# iqn_ail register map
Vendor: Texas Instruments
Peripheral module from a debugger description file (folder Keystone2).
Registers are 32-bit, read-only, no defined reset value unless marked. A register's access mark holds for its fields unless they carry their own. Offsets are as the file gives them; lines under a group give offsets from that group; [hi:lo] are bit positions; {n}, {i} and the like mark numbered series; 'fields as' and 'values as' point back to an identical list; <NAME> marks a mode.

## IQN_AIL (part 1 of 5)
0x3023C AIL_PHY_TM_Status_Register — (1 of 1, stride 0)
  [8:5] frm_state — Indicates that status of the Frame Sync state machine
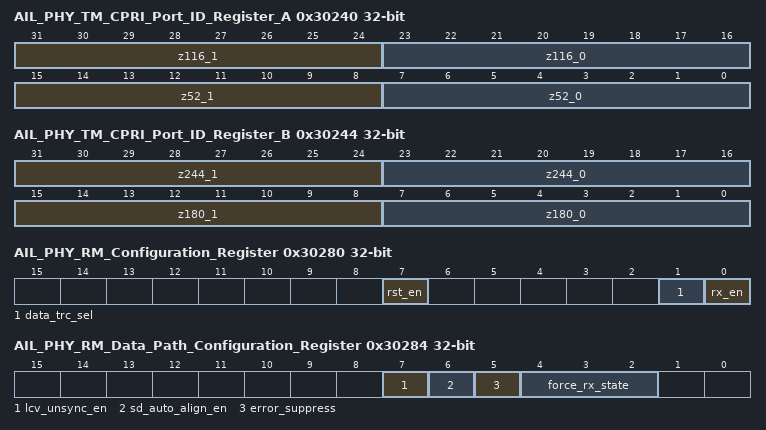
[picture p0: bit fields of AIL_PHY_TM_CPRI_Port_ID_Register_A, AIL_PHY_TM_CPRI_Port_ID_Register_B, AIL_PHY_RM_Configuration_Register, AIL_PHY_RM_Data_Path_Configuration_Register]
0x30240 AIL_PHY_TM_CPRI_Port_ID_Register_A rw — (1 of 1, stride 0)
  [31:24] z116_1 — Contains the Z.116.1 byte transmitted CPRI Port ID value
  [23:16] z116_0 — Contains the Z.116.0 byte transmitted CPRI Port ID value
  [15:8] z52_1 — Contains the Z.52.1 byte transmitted CPRI Port ID value
  [7:0] z52_0 — Contains the Z.52.0 byte transmitted CPRI Port ID value
0x30244 AIL_PHY_TM_CPRI_Port_ID_Register_B rw — (1 of 1, stride 0)
  [31:24] z244_1 — Contains the Z.244.1 byte transmitted CPRI Port ID value
  [23:16] z244_0 — Contains the Z.244.0 byte transmitted CPRI Port ID value
  [15:8] z180_1 — Contains the Z.180.1 byte transmitted CPRI Port ID value
  [7:0] z180_0 — Contains the Z.180.0 byte transmitted CPRI Port ID value
0x30248 AIL_PHY_TM_CPRI_Scrambler_Configuration rw — (1 of 1, stride 0)
  [30:0] seed_value — The seed value is used to initialize the transmit scrambler circuit
0x30280 AIL_PHY_RM_Configuration_Register rw — (1 of 1, stride 0)
  [7] rst_en — Enable CPRI SOC Reset Signal. 5 consecutive recieved active L1_Inband_rst will fire a signal to SOC core which can be enabled with an LPSC to perform HW reset of entire SOC
  [1] data_trc_sel — Data Trace Select. Selects between the raw data after 8b/10b decoding and framed data after the frame sync state machine and de-scrambling. for Data Trace data
  [0] rx_en — Enable RM Link FSM to activate on next recieved PHY frame boundary
0x30284 AIL_PHY_RM_Data_Path_Configuration_Register rw — (1 of 1, stride 0)
  [7] lcv_unsync_en — Enables a state transition from the ST3 to the ST0 state when lcv_det_thold is met
  [6] sd_auto_align_en — Enables the RM to automatically disable Serdes symbol alignment when the receiver state machine reaches state ST3
  [5] error_suppress — Suppress error reporting when the receiver state machine is not in state ST3
  [4:2] force_rx_state — Force RM receiver state machine state
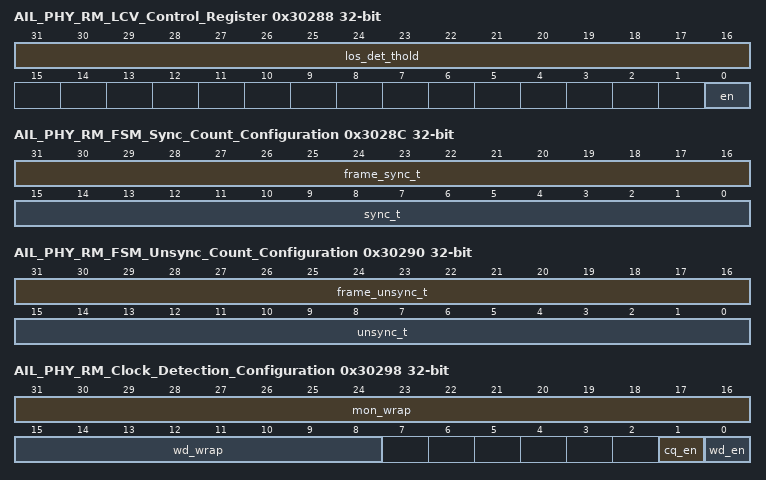
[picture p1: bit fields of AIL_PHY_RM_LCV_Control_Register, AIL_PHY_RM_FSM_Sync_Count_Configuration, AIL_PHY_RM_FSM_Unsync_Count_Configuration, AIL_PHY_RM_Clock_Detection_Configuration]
0x30288 AIL_PHY_RM_LCV_Control_Register rw — (1 of 1, stride 0)
  [31:16] los_det_thold — Sets 8b10b los detect threshold values in number of Line Code Violations received during a master frame, OBSAI, or during a Hyperframe, CPRI. Writing to this location will automatically clear the num_los counter and num_los_det status bit. Range 0 to
  [0] en — Writing a 1 to the bit will enable the Line Code Violation counter. This 16 bit counter will saturate when it reaches a value of 0xffff. Writing a 0 to this bit will clear and disable the counter. The current counter value is available as status,
0x3028C AIL_PHY_RM_FSM_Sync_Count_Configuration rw — (1 of 1, stride 0)
  [31:16] frame_sync_t — Threshold value for consecutive valid message groups which result in state ST3. Range 0 to 65,535
  [15:0] sync_t — Threshold value for consecutive valid blocks of bytes which result in state ST1. Range 0 to 65,535
0x30290 AIL_PHY_RM_FSM_Unsync_Count_Configuration rw — (1 of 1, stride 0)
  [31:16] frame_unsync_t — Threshold value for consecutive invalid message groups which result in state ST1. Range 0 to 65,535
  [15:0] unsync_t — Threshold value for consecutive invalid blocks of bytes which result in state ST0. Range 0 to 65,535
0x30294 AIL_PHY_RM_Descrambling_Control_Register rw — (1 of 1, stride 0)
  [7] scr_en — Enables the scrambler for operation in the receiver data path
0x30298 AIL_PHY_RM_Clock_Detection_Configuration rw — (1 of 1, stride 0)
  [31:16] mon_wrap — Defines the wrap value of the clock monitor used to define clock quality. A value of zero disables the clock monitor, Range 0 to 65,535
  [15:8] wd_wrap — Defines the wrap value of the clock detection watchdog circuit. A value of zero disables the clock watchdog timer, Range 0 to 255
  [1] cq_en — Enables the clock quality circuit.
  [0] wd_en — Enables the clock detect watch dog timer.
0x3029C AIL_PHY_RM_CPRI_Hyperframe_Status_Register — (1 of 1, stride 0)
  [7:0] hfn — Received hyperframe number, Z.64.0. Range 0 to 149 basic frames
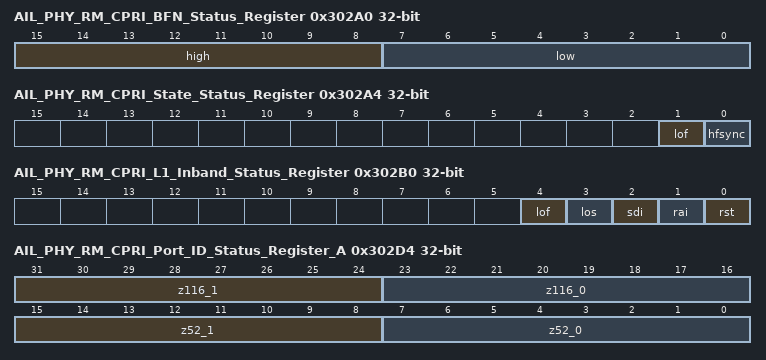
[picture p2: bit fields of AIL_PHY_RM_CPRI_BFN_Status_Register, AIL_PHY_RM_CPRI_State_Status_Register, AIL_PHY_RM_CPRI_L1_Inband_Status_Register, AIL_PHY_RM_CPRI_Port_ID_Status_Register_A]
0x302A0 AIL_PHY_RM_CPRI_BFN_Status_Register — (1 of 1, stride 0)
  [15:8] high — Received Node B Frame number high byte, Z.130.0
  [7:0] low — Received Node B Frame number low byte, Z.128.0
0x302A4 AIL_PHY_RM_CPRI_State_Status_Register — (1 of 1, stride 0)
  [1] lof — Active high status indicates Loss Of Frame when the receiver FSM is in state ST0 or ST1. NOTE.. The value of this bit will be 0 after reset but will change to a value of 1 if CPRI mode is enabled.
  [0] hfsync — Active high status indicates when the receiber FSM is in the HFSYNC state ST3
0x302A8 AIL_PHY_RM_CPRI_Version_Status_Register — (1 of 1, stride 0)
  [7:0] value — Received protocol version, Z.2.0
0x302AC AIL_PHY_RM_CPRI_Startup_Status_Register — (1 of 1, stride 0)
  [7:0] value — Received start up information, Z.66.0
0x302B0 AIL_PHY_RM_CPRI_L1_Inband_Status_Register — (1 of 1, stride 0)
  [4] lof — Received sdi, Z.130.0, b4
  [3] los — Received sdi, Z.130.0, b3
  [2] sdi — Received sdi, Z.130.0, b2
  [1] rai — Received rai, Z.130.0, b1
  [0] rst — Received reset, Z.130.0, b0
0x302B4 AIL_PHY_RM_CPRI_Pointer_P_Status_Register — (1 of 1, stride 0)
  [7:0] pntr_p — Received Pointer P
0x302B8 AIL_PHY_RM_CPRI_De_scrambler_Seed_Status — (1 of 1, stride 0)
  [30:0] value — Indicates the captured scrambling code, only when configuration bit scr_en = 1 in CPRI mode.
0x302C0 AIL_PHY_RM_Status_Register — (1 of 1, stride 0)
  [15:10] rx_sync — Indicates the current status of the RX state machine
0x302C4 AIL_PHY_RM_LCV_LOS_Count_Status_Register — (1 of 1, stride 0)
  [15:0] num — Represents the number of los_det, 8b10b code violation, occurrences in a mater frame, in OBSAI, or hyperframe, in CPRI. This counter will saturate and hold its value until either cleared by writing the configuration value los_det_thold = 0 or after a
0x302C8 AIL_PHY_RM_LCV_Count_Status_Register — (1 of 1, stride 0)
  [15:0] value — Number of Line Code Violations counted since last cleared and enabled. Range 0 to 65,535
0x302CC AIL_PHY_RM_Clock_Quality_Status_Register — (1 of 1, stride 0)
  [15:0] value — A value that represents the quality, relative frequency, of the received Serdes clock. Range 0 to 65,535
0x302D0 AIL_PHY_RM_OBSAI_De_Scrambler_Seed_Status — (1 of 1, stride 0)
  [6:0] value — Indicates the captured scrambling code, only when configuration bit scr_en = 1.
0x302D4 AIL_PHY_RM_CPRI_Port_ID_Status_Register_A — (1 of 1, stride 0)
  [31:24] z116_1 — Contains the Z.116.1 byte received CPRI Port ID value
  [23:16] z116_0 — Contains the Z.116.0 byte received CPRI Port ID value
  [15:8] z52_1 — Contains the Z.52.1 byte received CPRI Port ID value
  [7:0] z52_0 — Contains the Z.52.0 byte received CPRI Port ID value
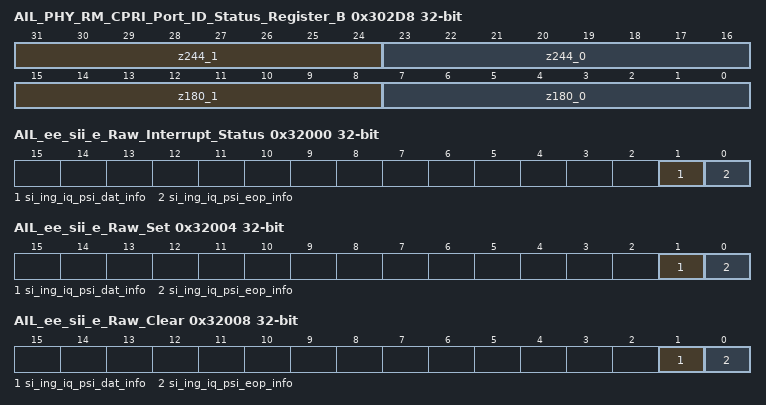
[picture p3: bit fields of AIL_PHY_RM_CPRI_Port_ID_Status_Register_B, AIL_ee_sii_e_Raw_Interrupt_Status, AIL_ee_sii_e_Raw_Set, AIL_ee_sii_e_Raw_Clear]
0x302D8 AIL_PHY_RM_CPRI_Port_ID_Status_Register_B — (1 of 1, stride 0)
  [31:24] z244_1 — Contains the Z.244.1 byte received CPRI Port ID value
  [23:16] z244_0 — Contains the Z.244.0 byte received CPRI Port ID value
  [15:8] z180_1 — Contains the Z.180.1 byte received CPRI Port ID value
  [7:0] z180_0 — Contains the Z.180.0 byte received CPRI Port ID value
0x32000 AIL_ee_sii_e_Raw_Interrupt_Status — (1 of 1, stride 0)
  [1] si_ing_iq_psi_dat_info — SI Ingress IQ data transmitted to PSI
  [0] si_ing_iq_psi_eop_info — SI Ingress IQ EOP transmitted to PSI
0x32004 AIL_ee_sii_e_Raw_Set wo — (1 of 1, stride 0)
  [1] si_ing_iq_psi_dat_info — Sets the corresponding bit in the raw_status register when set. Write only, self-clears.
  [0] si_ing_iq_psi_eop_info — Sets the corresponding bit in the raw_status register when set. Write only, self-clears.
0x32008 AIL_ee_sii_e_Raw_Clear wo — (1 of 1, stride 0)
  [1] si_ing_iq_psi_dat_info — Clears the corresponding bit in the raw_status register when set. Write only, self-clears.
  [0] si_ing_iq_psi_eop_info — Clears the corresponding bit in the raw_status register when set. Write only, self-clears.
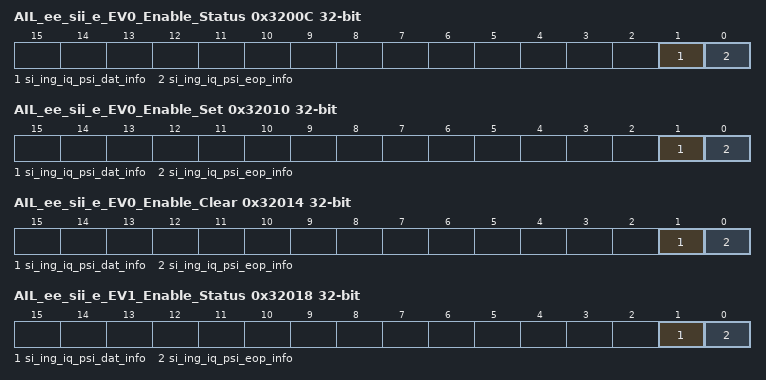
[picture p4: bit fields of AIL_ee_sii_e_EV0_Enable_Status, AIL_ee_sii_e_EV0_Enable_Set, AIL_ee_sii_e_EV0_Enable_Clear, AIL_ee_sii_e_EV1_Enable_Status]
0x3200C AIL_ee_sii_e_EV0_Enable_Status — (1 of 1, stride 0)
  [1] si_ing_iq_psi_dat_info — When set allows the corresponding bit in the raw_status register to generate the intr_sts interrupt. Read only.
  [0] si_ing_iq_psi_eop_info — When set allows the corresponding bit in the raw_status register to generate the intr_sts interrupt. Read only.
0x32010 AIL_ee_sii_e_EV0_Enable_Set wo — (1 of 1, stride 0)
  [1] si_ing_iq_psi_dat_info — Sets the corresponding bit in the enable register when set. Write only, self-clears.
  [0] si_ing_iq_psi_eop_info — Sets the corresponding bit in the enable register when set. Write only, self-clears.
0x32014 AIL_ee_sii_e_EV0_Enable_Clear wo — (1 of 1, stride 0)
  [1] si_ing_iq_psi_dat_info — Clears the corresponding bit in the enable register when set. Write only, self-clears.
  [0] si_ing_iq_psi_eop_info — Clears the corresponding bit in the enable register when set. Write only, self-clears.
0x32018 AIL_ee_sii_e_EV1_Enable_Status — (1 of 1, stride 0)
  [1] si_ing_iq_psi_dat_info — When set allows the corresponding bit in the raw_status register to generate the intr1_sts interrupt. Read only.
  [0] si_ing_iq_psi_eop_info — When set allows the corresponding bit in the raw_status register to generate the intr1_sts interrupt. Read only.
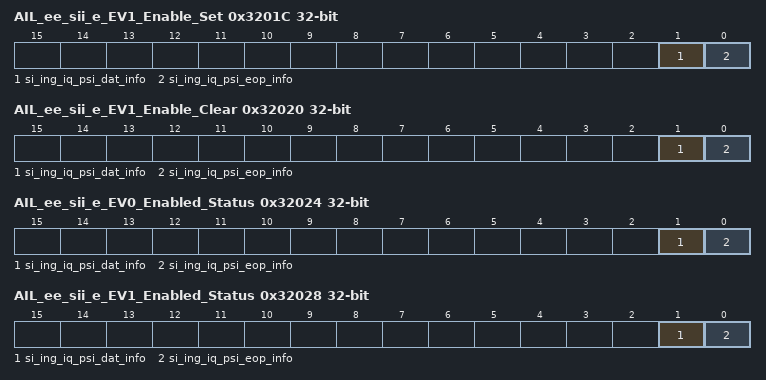
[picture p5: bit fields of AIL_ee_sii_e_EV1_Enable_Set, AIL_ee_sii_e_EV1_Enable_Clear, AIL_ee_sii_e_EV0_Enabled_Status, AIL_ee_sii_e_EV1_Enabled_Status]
0x3201C AIL_ee_sii_e_EV1_Enable_Set wo — (1 of 1, stride 0)
  [1] si_ing_iq_psi_dat_info — Sets the corresponding bit in the intr1_status register when set. Write only, self-clears.
  [0] si_ing_iq_psi_eop_info — Sets the corresponding bit in the intr1_status register when set. Write only, self-clears.
0x32020 AIL_ee_sii_e_EV1_Enable_Clear wo — (1 of 1, stride 0)
  [1] si_ing_iq_psi_dat_info — Clears the corresponding bit in the intr1_status register when set. Write only, self-clears.
  [0] si_ing_iq_psi_eop_info — Clears the corresponding bit in the intr1_status register when set. Write only, self-clears.
0x32024 AIL_ee_sii_e_EV0_Enabled_Status — (1 of 1, stride 0)
  [1] si_ing_iq_psi_dat_info — AND-ed raw_status bits with the corresponding bit in the enable_status register. Read only.
  [0] si_ing_iq_psi_eop_info — AND-ed raw_status bits with the corresponding bit in the enable_status register. Read only.
0x32028 AIL_ee_sii_e_EV1_Enabled_Status — (1 of 1, stride 0)
  [1] si_ing_iq_psi_dat_info — AND-ed raw_status bits with the corresponding bit in the intr1_status register. Read only.
  [0] si_ing_iq_psi_eop_info — AND-ed raw_status bits with the corresponding bit in the intr1_status register. Read only.
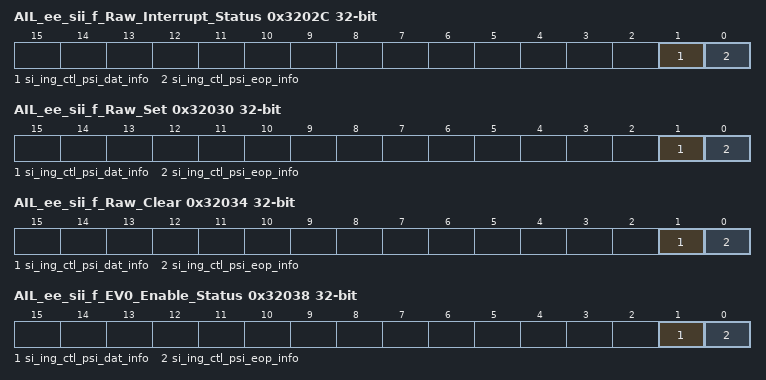
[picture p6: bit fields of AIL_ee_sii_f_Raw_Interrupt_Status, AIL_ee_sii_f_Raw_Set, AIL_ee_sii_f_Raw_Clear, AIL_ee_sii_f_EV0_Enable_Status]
0x3202C AIL_ee_sii_f_Raw_Interrupt_Status — (1 of 1, stride 0)
  [1] si_ing_ctl_psi_dat_info — SI Ingress CTL data transmitted to PSI
  [0] si_ing_ctl_psi_eop_info — SI Ingress CTL EOP transmitted to PSI
0x32030 AIL_ee_sii_f_Raw_Set wo — (1 of 1, stride 0)
  [1] si_ing_ctl_psi_dat_info — Sets the corresponding bit in the raw_status register when set. Write only, self-clears.
  [0] si_ing_ctl_psi_eop_info — Sets the corresponding bit in the raw_status register when set. Write only, self-clears.
0x32034 AIL_ee_sii_f_Raw_Clear wo — (1 of 1, stride 0)
  [1] si_ing_ctl_psi_dat_info — Clears the corresponding bit in the raw_status register when set. Write only, self-clears.
  [0] si_ing_ctl_psi_eop_info — Clears the corresponding bit in the raw_status register when set. Write only, self-clears.
0x32038 AIL_ee_sii_f_EV0_Enable_Status — (1 of 1, stride 0)
  [1] si_ing_ctl_psi_dat_info — When set allows the corresponding bit in the raw_status register to generate the intr_sts interrupt. Read only.
  [0] si_ing_ctl_psi_eop_info — When set allows the corresponding bit in the raw_status register to generate the intr_sts interrupt. Read only.
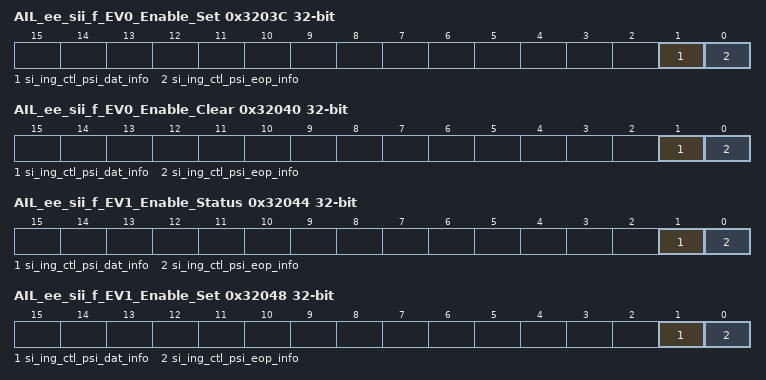
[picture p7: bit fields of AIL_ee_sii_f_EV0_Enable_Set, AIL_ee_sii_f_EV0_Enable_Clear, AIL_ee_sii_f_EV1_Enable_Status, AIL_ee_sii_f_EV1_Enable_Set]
0x3203C AIL_ee_sii_f_EV0_Enable_Set wo — (1 of 1, stride 0)
  [1] si_ing_ctl_psi_dat_info — Sets the corresponding bit in the enable register when set. Write only, self-clears.
  [0] si_ing_ctl_psi_eop_info — Sets the corresponding bit in the enable register when set. Write only, self-clears.
0x32040 AIL_ee_sii_f_EV0_Enable_Clear wo — (1 of 1, stride 0)
  [1] si_ing_ctl_psi_dat_info — Clears the corresponding bit in the enable register when set. Write only, self-clears.
  [0] si_ing_ctl_psi_eop_info — Clears the corresponding bit in the enable register when set. Write only, self-clears.
0x32044 AIL_ee_sii_f_EV1_Enable_Status — (1 of 1, stride 0)
  [1] si_ing_ctl_psi_dat_info — When set allows the corresponding bit in the raw_status register to generate the intr1_sts interrupt. Read only.
  [0] si_ing_ctl_psi_eop_info — When set allows the corresponding bit in the raw_status register to generate the intr1_sts interrupt. Read only.
0x32048 AIL_ee_sii_f_EV1_Enable_Set wo — (1 of 1, stride 0)
  [1] si_ing_ctl_psi_dat_info — Sets the corresponding bit in the intr1_status register when set. Write only, self-clears.
  [0] si_ing_ctl_psi_eop_info — Sets the corresponding bit in the intr1_status register when set. Write only, self-clears.
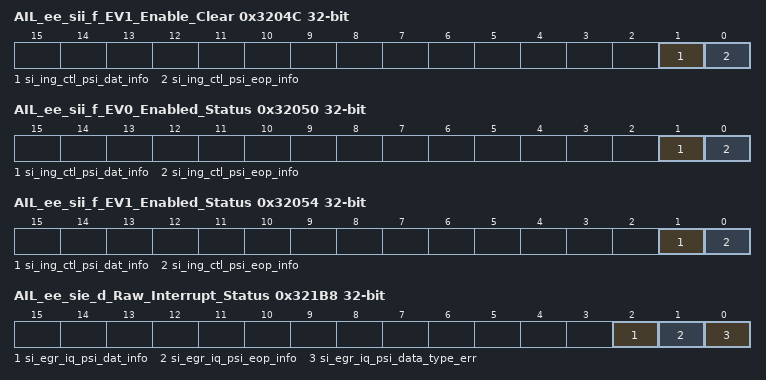
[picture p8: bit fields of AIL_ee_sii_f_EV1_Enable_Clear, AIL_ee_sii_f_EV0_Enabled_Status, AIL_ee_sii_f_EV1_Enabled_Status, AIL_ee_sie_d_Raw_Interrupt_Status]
0x3204C AIL_ee_sii_f_EV1_Enable_Clear wo — (1 of 1, stride 0)
  [1] si_ing_ctl_psi_dat_info — Clears the corresponding bit in the intr1_status register when set. Write only, self-clears.
  [0] si_ing_ctl_psi_eop_info — Clears the corresponding bit in the intr1_status register when set. Write only, self-clears.
0x32050 AIL_ee_sii_f_EV0_Enabled_Status — (1 of 1, stride 0)
  [1] si_ing_ctl_psi_dat_info — AND-ed raw_status bits with the corresponding bit in the enable_status register. Read only.
  [0] si_ing_ctl_psi_eop_info — AND-ed raw_status bits with the corresponding bit in the enable_status register. Read only.
0x32054 AIL_ee_sii_f_EV1_Enabled_Status — (1 of 1, stride 0)
  [1] si_ing_ctl_psi_dat_info — AND-ed raw_status bits with the corresponding bit in the intr1_status register. Read only.
  [0] si_ing_ctl_psi_eop_info — AND-ed raw_status bits with the corresponding bit in the intr1_status register. Read only.
0x32058 AIL_ee_sii_g_0_Raw_Interrupt_Status — (1 of 1, stride 0)
  [31:0] si_ing_iq_psi_sop_info — SI Ingress IQ SOP transmitted to PSI
0x3205C AIL_ee_sii_g_0_Raw_Set wo — (1 of 1, stride 0)
  [31:0] si_ing_iq_psi_sop_info — Sets the corresponding bit in the raw_status register when set. Write only, self-clears.
0x32060 AIL_ee_sii_g_0_Raw_Clear wo — (1 of 1, stride 0)
  [31:0] si_ing_iq_psi_sop_info — Clears the corresponding bit in the raw_status register when set. Write only, self-clears.
0x32064 AIL_ee_sii_g_0_EV0_Enable_Status — (1 of 1, stride 0)
  [31:0] si_ing_iq_psi_sop_info — When set allows the corresponding bit in the raw_status register to generate the intr_sts interrupt. Read only.
0x32068 AIL_ee_sii_g_0_EV0_Enable_Set wo — (1 of 1, stride 0)
  [31:0] si_ing_iq_psi_sop_info — Sets the corresponding bit in the enable register when set. Write only, self-clears.
0x3206C AIL_ee_sii_g_0_EV0_Enable_Clear wo — (1 of 1, stride 0)
  [31:0] si_ing_iq_psi_sop_info — Clears the corresponding bit in the enable register when set. Write only, self-clears.
0x32070 AIL_ee_sii_g_0_EV1_Enable_Status — (1 of 1, stride 0)
  [31:0] si_ing_iq_psi_sop_info — When set allows the corresponding bit in the raw_status register to generate the intr1_sts interrupt. Read only.
0x32074 AIL_ee_sii_g_0_EV1_Enable_Set wo — (1 of 1, stride 0)
  [31:0] si_ing_iq_psi_sop_info — Sets the corresponding bit in the intr1_status register when set. Write only, self-clears.
0x32078 AIL_ee_sii_g_0_EV1_Enable_Clear wo — (1 of 1, stride 0)
  [31:0] si_ing_iq_psi_sop_info — Clears the corresponding bit in the intr1_status register when set. Write only, self-clears.
0x3207C AIL_ee_sii_g_0_EV0_Enabled_Status — (1 of 1, stride 0)
  [31:0] si_ing_iq_psi_sop_info — AND-ed raw_status bits with the corresponding bit in the enable_status register. Read only.
0x32080 AIL_ee_sii_g_0_EV1_Enabled_Status — (1 of 1, stride 0)
  [31:0] si_ing_iq_psi_sop_info — AND-ed raw_status bits with the corresponding bit in the intr1_status register. Read only.
0x32084 AIL_ee_sii_g_1_Raw_Interrupt_Status — (1 of 1, stride 0)
  [31:0] si_ing_iq_psi_sop_info_64_32 — SI Ingress IQ SOP transmitted to PSI
0x32088 AIL_ee_sii_g_1_Raw_Set wo — (1 of 1, stride 0)
  [31:0] si_ing_iq_psi_sop_info_64_32 — Sets the corresponding bit in the raw_status register when set. Write only, self-clears.
0x3208C AIL_ee_sii_g_1_Raw_Clear wo — (1 of 1, stride 0)
  [31:0] si_ing_iq_psi_sop_info_64_32 — Clears the corresponding bit in the raw_status register when set. Write only, self-clears.
0x32090 AIL_ee_sii_g_1_EV0_Enable_Status — (1 of 1, stride 0)
  [31:0] si_ing_iq_psi_sop_info_64_32 — When set allows the corresponding bit in the raw_status register to generate the intr_sts interrupt. Read only.
0x32094 AIL_ee_sii_g_1_EV0_Enable_Set wo — (1 of 1, stride 0)
  [31:0] si_ing_iq_psi_sop_info_64_32 — Sets the corresponding bit in the enable register when set. Write only, self-clears.
0x32098 AIL_ee_sii_g_1_EV0_Enable_Clear wo — (1 of 1, stride 0)
  [31:0] si_ing_iq_psi_sop_info_64_32 — Clears the corresponding bit in the enable register when set. Write only, self-clears.
0x3209C AIL_ee_sii_g_1_EV1_Enable_Status — (1 of 1, stride 0)
  [31:0] si_ing_iq_psi_sop_info_64_32 — When set allows the corresponding bit in the raw_status register to generate the intr1_sts interrupt. Read only.
0x320A0 AIL_ee_sii_g_1_EV1_Enable_Set wo — (1 of 1, stride 0)
  [31:0] si_ing_iq_psi_sop_info_64_32 — Sets the corresponding bit in the intr1_status register when set. Write only, self-clears.
0x320A4 AIL_ee_sii_g_1_EV1_Enable_Clear wo — (1 of 1, stride 0)
  [31:0] si_ing_iq_psi_sop_info_64_32 — Clears the corresponding bit in the intr1_status register when set. Write only, self-clears.
0x320A8 AIL_ee_sii_g_1_EV0_Enabled_Status — (1 of 1, stride 0)
  [31:0] si_ing_iq_psi_sop_info_64_32 — AND-ed raw_status bits with the corresponding bit in the enable_status register. Read only.
0x320AC AIL_ee_sii_g_1_EV1_Enabled_Status — (1 of 1, stride 0)
  [31:0] si_ing_iq_psi_sop_info_64_32 — AND-ed raw_status bits with the corresponding bit in the intr1_status register. Read only.
0x32108 AIL_ee_sii_h_Raw_Interrupt_Status — (1 of 1, stride 0)
  [3:0] si_ing_ctl_psi_sop_info — SI Ingress CTL per channel SOP transmitted to PSI
0x3210C AIL_ee_sii_h_Raw_Set wo — (1 of 1, stride 0)
  [3:0] si_ing_ctl_psi_sop_info — Sets the corresponding bit in the raw_status register when set. Write only, self-clears.
0x32110 AIL_ee_sii_h_Raw_Clear wo — (1 of 1, stride 0)
  [3:0] si_ing_ctl_psi_sop_info — Clears the corresponding bit in the raw_status register when set. Write only, self-clears.
0x32114 AIL_ee_sii_h_EV0_Enable_Status — (1 of 1, stride 0)
  [3:0] si_ing_ctl_psi_sop_info — When set allows the corresponding bit in the raw_status register to generate the intr_sts interrupt. Read only.
0x32118 AIL_ee_sii_h_EV0_Enable_Set wo — (1 of 1, stride 0)
  [3:0] si_ing_ctl_psi_sop_info — Sets the corresponding bit in the enable register when set. Write only, self-clears.
0x3211C AIL_ee_sii_h_EV0_Enable_Clear wo — (1 of 1, stride 0)
  [3:0] si_ing_ctl_psi_sop_info — Clears the corresponding bit in the enable register when set. Write only, self-clears.
0x32120 AIL_ee_sii_h_EV1_Enable_Status — (1 of 1, stride 0)
  [3:0] si_ing_ctl_psi_sop_info — When set allows the corresponding bit in the raw_status register to generate the intr1_sts interrupt. Read only.
0x32124 AIL_ee_sii_h_EV1_Enable_Set wo — (1 of 1, stride 0)
  [3:0] si_ing_ctl_psi_sop_info — Sets the corresponding bit in the intr1_status register when set. Write only, self-clears.
0x32128 AIL_ee_sii_h_EV1_Enable_Clear wo — (1 of 1, stride 0)
  [3:0] si_ing_ctl_psi_sop_info — Clears the corresponding bit in the intr1_status register when set. Write only, self-clears.
0x3212C AIL_ee_sii_h_EV0_Enabled_Status — (1 of 1, stride 0)
  [3:0] si_ing_ctl_psi_sop_info — AND-ed raw_status bits with the corresponding bit in the enable_status register. Read only.
0x32130 AIL_ee_sii_h_EV1_Enabled_Status — (1 of 1, stride 0)
  [3:0] si_ing_ctl_psi_sop_info — AND-ed raw_status bits with the corresponding bit in the intr1_status register. Read only.
0x321B8 AIL_ee_sie_d_Raw_Interrupt_Status — (1 of 1, stride 0)
  [2] si_egr_iq_psi_dat_info — SI Egress IQ valid data received from PSI
  [1] si_egr_iq_psi_eop_info — SI Egress IQ EOP received from PSI
  [0] si_egr_iq_psi_data_type_err — SI Egress IQ PSI data type error
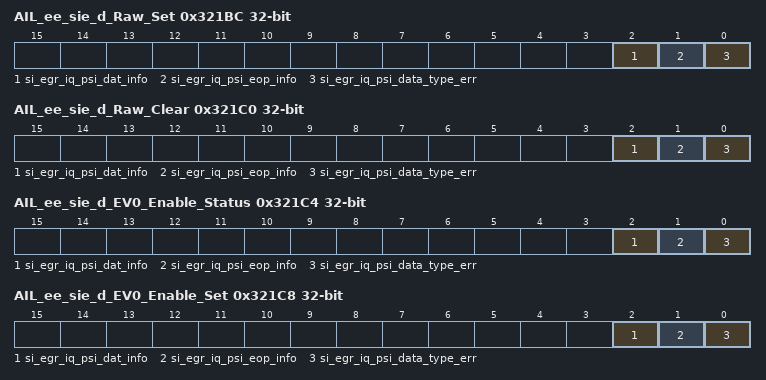
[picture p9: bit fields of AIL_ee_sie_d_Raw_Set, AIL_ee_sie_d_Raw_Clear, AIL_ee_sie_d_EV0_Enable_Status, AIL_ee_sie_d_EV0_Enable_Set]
0x321BC AIL_ee_sie_d_Raw_Set wo — (1 of 1, stride 0)
  [2] si_egr_iq_psi_dat_info — Sets the corresponding bit in the raw_status register when set. Write only, self-clears.
  [1] si_egr_iq_psi_eop_info — Sets the corresponding bit in the raw_status register when set. Write only, self-clears.
  [0] si_egr_iq_psi_data_type_err — Sets the corresponding bit in the raw_status register when set. Write only, self-clears.
0x321C0 AIL_ee_sie_d_Raw_Clear wo — (1 of 1, stride 0)
  [2] si_egr_iq_psi_dat_info — Clears the corresponding bit in the raw_status register when set. Write only, self-clears.
  [1] si_egr_iq_psi_eop_info — Clears the corresponding bit in the raw_status register when set. Write only, self-clears.
  [0] si_egr_iq_psi_data_type_err — Clears the corresponding bit in the raw_status register when set. Write only, self-clears.
0x321C4 AIL_ee_sie_d_EV0_Enable_Status — (1 of 1, stride 0)
  [2] si_egr_iq_psi_dat_info — When set allows the corresponding bit in the raw_status register to generate the intr_sts interrupt. Read only.
  [1] si_egr_iq_psi_eop_info — When set allows the corresponding bit in the raw_status register to generate the intr_sts interrupt. Read only.
  [0] si_egr_iq_psi_data_type_err — When set allows the corresponding bit in the raw_status register to generate the intr_sts interrupt. Read only.
0x321C8 AIL_ee_sie_d_EV0_Enable_Set wo — (1 of 1, stride 0)
  [2] si_egr_iq_psi_dat_info — Sets the corresponding bit in the enable register when set. Write only, self-clears.
  [1] si_egr_iq_psi_eop_info — Sets the corresponding bit in the enable register when set. Write only, self-clears.
  [0] si_egr_iq_psi_data_type_err — Sets the corresponding bit in the enable register when set. Write only, self-clears.
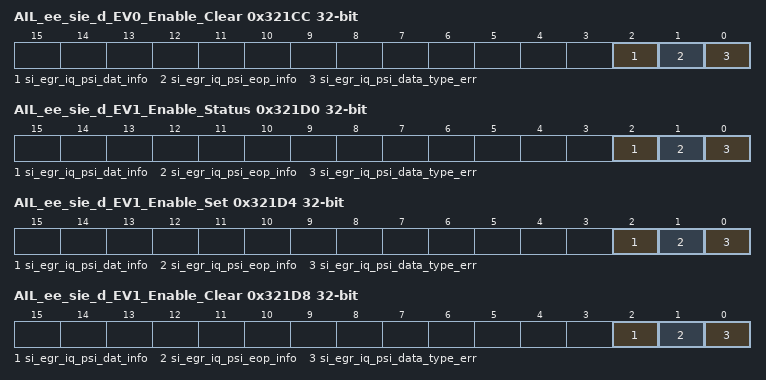
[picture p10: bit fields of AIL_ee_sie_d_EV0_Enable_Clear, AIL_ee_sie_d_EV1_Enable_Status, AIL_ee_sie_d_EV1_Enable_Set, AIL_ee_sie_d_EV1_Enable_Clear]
0x321CC AIL_ee_sie_d_EV0_Enable_Clear wo — (1 of 1, stride 0)
  [2] si_egr_iq_psi_dat_info — Clears the corresponding bit in the enable register when set. Write only, self-clears.
  [1] si_egr_iq_psi_eop_info — Clears the corresponding bit in the enable register when set. Write only, self-clears.
  [0] si_egr_iq_psi_data_type_err — Clears the corresponding bit in the enable register when set. Write only, self-clears.
0x321D0 AIL_ee_sie_d_EV1_Enable_Status — (1 of 1, stride 0)
  [2] si_egr_iq_psi_dat_info — When set allows the corresponding bit in the raw_status register to generate the intr1_sts interrupt. Read only.
  [1] si_egr_iq_psi_eop_info — When set allows the corresponding bit in the raw_status register to generate the intr1_sts interrupt. Read only.
  [0] si_egr_iq_psi_data_type_err — When set allows the corresponding bit in the raw_status register to generate the intr1_sts interrupt. Read only.
0x321D4 AIL_ee_sie_d_EV1_Enable_Set wo — (1 of 1, stride 0)
  [2] si_egr_iq_psi_dat_info — Sets the corresponding bit in the intr1_status register when set. Write only, self-clears.
  [1] si_egr_iq_psi_eop_info — Sets the corresponding bit in the intr1_status register when set. Write only, self-clears.
  [0] si_egr_iq_psi_data_type_err — Sets the corresponding bit in the intr1_status register when set. Write only, self-clears.
0x321D8 AIL_ee_sie_d_EV1_Enable_Clear wo — (1 of 1, stride 0)
  [2] si_egr_iq_psi_dat_info — Clears the corresponding bit in the intr1_status register when set. Write only, self-clears.
  [1] si_egr_iq_psi_eop_info — Clears the corresponding bit in the intr1_status register when set. Write only, self-clears.
  [0] si_egr_iq_psi_data_type_err — Clears the corresponding bit in the intr1_status register when set. Write only, self-clears.
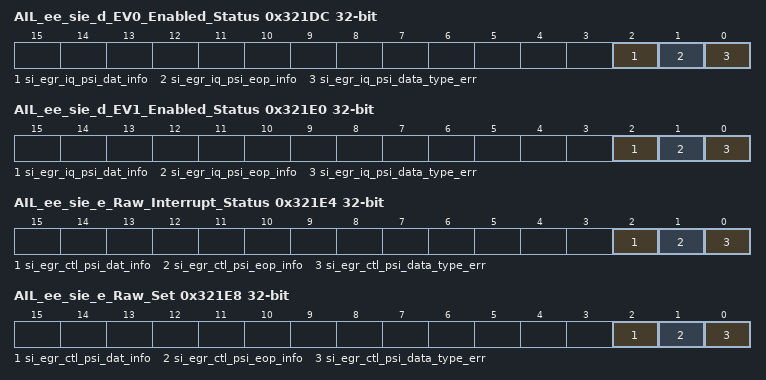
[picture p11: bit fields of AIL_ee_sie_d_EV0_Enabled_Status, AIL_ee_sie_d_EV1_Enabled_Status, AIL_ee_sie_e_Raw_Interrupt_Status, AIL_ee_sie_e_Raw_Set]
0x321DC AIL_ee_sie_d_EV0_Enabled_Status — (1 of 1, stride 0)
  [2] si_egr_iq_psi_dat_info — AND-ed raw_status bits with the corresponding bit in the enable_status register. Read only.
  [1] si_egr_iq_psi_eop_info — AND-ed raw_status bits with the corresponding bit in the enable_status register. Read only.
  [0] si_egr_iq_psi_data_type_err — AND-ed raw_status bits with the corresponding bit in the enable_status register. Read only.
0x321E0 AIL_ee_sie_d_EV1_Enabled_Status — (1 of 1, stride 0)
  [2] si_egr_iq_psi_dat_info — AND-ed raw_status bits with the corresponding bit in the intr1_status register. Read only.
  [1] si_egr_iq_psi_eop_info — AND-ed raw_status bits with the corresponding bit in the intr1_status register. Read only.
  [0] si_egr_iq_psi_data_type_err — AND-ed raw_status bits with the corresponding bit in the intr1_status register. Read only.
0x321E4 AIL_ee_sie_e_Raw_Interrupt_Status — (1 of 1, stride 0)
  [2] si_egr_ctl_psi_dat_info — SI Egress CTL valid data received from PSI
  [1] si_egr_ctl_psi_eop_info — SI Egress CTL EOP received from PSI
  [0] si_egr_ctl_psi_data_type_err — SI Egress CTL PSI data type error
0x321E8 AIL_ee_sie_e_Raw_Set wo — (1 of 1, stride 0)
  [2] si_egr_ctl_psi_dat_info — Sets the corresponding bit in the raw_status register when set. Write only, self-clears.
  [1] si_egr_ctl_psi_eop_info — Sets the corresponding bit in the raw_status register when set. Write only, self-clears.
  [0] si_egr_ctl_psi_data_type_err — Sets the corresponding bit in the raw_status register when set. Write only, self-clears.
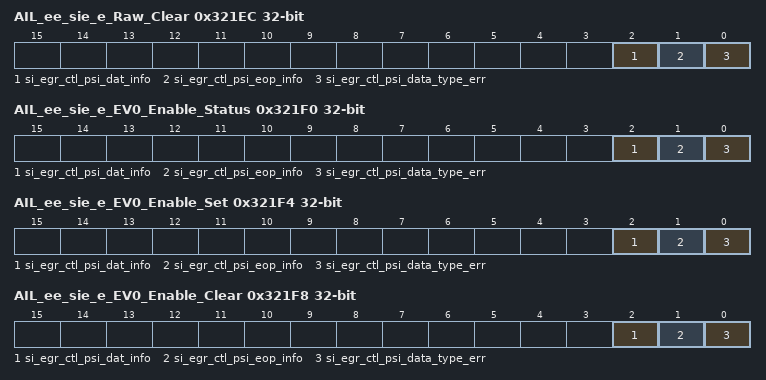
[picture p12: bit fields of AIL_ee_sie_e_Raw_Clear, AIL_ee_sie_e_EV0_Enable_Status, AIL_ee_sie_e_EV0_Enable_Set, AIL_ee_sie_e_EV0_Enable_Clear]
0x321EC AIL_ee_sie_e_Raw_Clear wo — (1 of 1, stride 0)
  [2] si_egr_ctl_psi_dat_info — Clears the corresponding bit in the raw_status register when set. Write only, self-clears.
  [1] si_egr_ctl_psi_eop_info — Clears the corresponding bit in the raw_status register when set. Write only, self-clears.
  [0] si_egr_ctl_psi_data_type_err — Clears the corresponding bit in the raw_status register when set. Write only, self-clears.
0x321F0 AIL_ee_sie_e_EV0_Enable_Status — (1 of 1, stride 0)
  [2] si_egr_ctl_psi_dat_info — When set allows the corresponding bit in the raw_status register to generate the intr_sts interrupt. Read only.
  [1] si_egr_ctl_psi_eop_info — When set allows the corresponding bit in the raw_status register to generate the intr_sts interrupt. Read only.
  [0] si_egr_ctl_psi_data_type_err — When set allows the corresponding bit in the raw_status register to generate the intr_sts interrupt. Read only.
0x321F4 AIL_ee_sie_e_EV0_Enable_Set wo — (1 of 1, stride 0)
  [2] si_egr_ctl_psi_dat_info — Sets the corresponding bit in the enable register when set. Write only, self-clears.
  [1] si_egr_ctl_psi_eop_info — Sets the corresponding bit in the enable register when set. Write only, self-clears.
  [0] si_egr_ctl_psi_data_type_err — Sets the corresponding bit in the enable register when set. Write only, self-clears.
0x321F8 AIL_ee_sie_e_EV0_Enable_Clear wo — (1 of 1, stride 0)
  [2] si_egr_ctl_psi_dat_info — Clears the corresponding bit in the enable register when set. Write only, self-clears.
  [1] si_egr_ctl_psi_eop_info — Clears the corresponding bit in the enable register when set. Write only, self-clears.
  [0] si_egr_ctl_psi_data_type_err — Clears the corresponding bit in the enable register when set. Write only, self-clears.
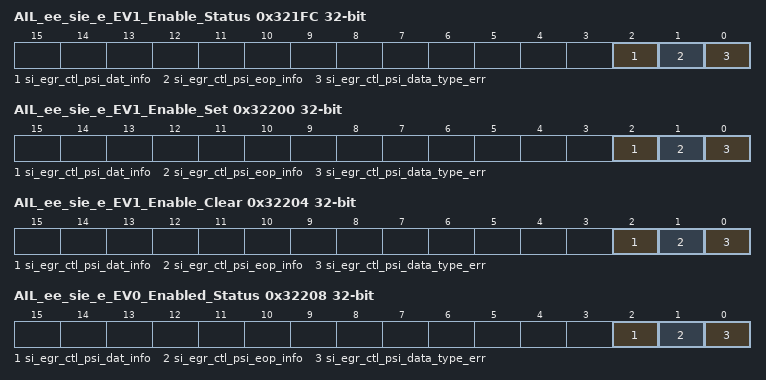
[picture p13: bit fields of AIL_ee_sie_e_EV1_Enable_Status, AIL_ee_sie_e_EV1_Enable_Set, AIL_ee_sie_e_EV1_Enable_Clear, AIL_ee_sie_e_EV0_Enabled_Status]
0x321FC AIL_ee_sie_e_EV1_Enable_Status — (1 of 1, stride 0)
  [2] si_egr_ctl_psi_dat_info — When set allows the corresponding bit in the raw_status register to generate the intr1_sts interrupt. Read only.
  [1] si_egr_ctl_psi_eop_info — When set allows the corresponding bit in the raw_status register to generate the intr1_sts interrupt. Read only.
  [0] si_egr_ctl_psi_data_type_err — When set allows the corresponding bit in the raw_status register to generate the intr1_sts interrupt. Read only.
0x32200 AIL_ee_sie_e_EV1_Enable_Set wo — (1 of 1, stride 0)
  [2] si_egr_ctl_psi_dat_info — Sets the corresponding bit in the intr1_status register when set. Write only, self-clears.
  [1] si_egr_ctl_psi_eop_info — Sets the corresponding bit in the intr1_status register when set. Write only, self-clears.
  [0] si_egr_ctl_psi_data_type_err — Sets the corresponding bit in the intr1_status register when set. Write only, self-clears.
0x32204 AIL_ee_sie_e_EV1_Enable_Clear wo — (1 of 1, stride 0)
  [2] si_egr_ctl_psi_dat_info — Clears the corresponding bit in the intr1_status register when set. Write only, self-clears.
  [1] si_egr_ctl_psi_eop_info — Clears the corresponding bit in the intr1_status register when set. Write only, self-clears.
  [0] si_egr_ctl_psi_data_type_err — Clears the corresponding bit in the intr1_status register when set. Write only, self-clears.
0x32208 AIL_ee_sie_e_EV0_Enabled_Status — (1 of 1, stride 0)
  [2] si_egr_ctl_psi_dat_info — AND-ed raw_status bits with the corresponding bit in the enable_status register. Read only.
  [1] si_egr_ctl_psi_eop_info — AND-ed raw_status bits with the corresponding bit in the enable_status register. Read only.
  [0] si_egr_ctl_psi_data_type_err — AND-ed raw_status bits with the corresponding bit in the enable_status register. Read only.
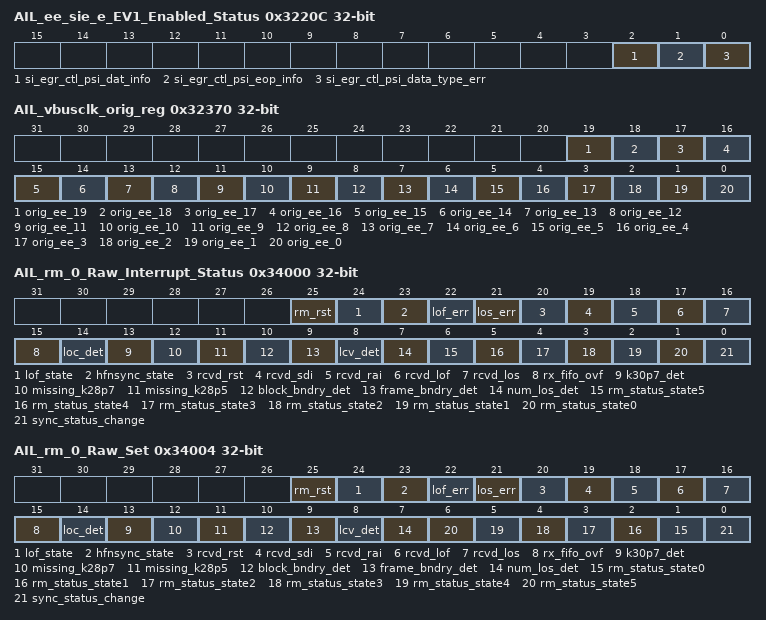
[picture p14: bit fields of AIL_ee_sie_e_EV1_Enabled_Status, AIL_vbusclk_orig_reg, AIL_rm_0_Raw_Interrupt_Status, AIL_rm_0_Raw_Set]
0x3220C AIL_ee_sie_e_EV1_Enabled_Status — (1 of 1, stride 0)
  [2] si_egr_ctl_psi_dat_info — AND-ed raw_status bits with the corresponding bit in the intr1_status register. Read only.
  [1] si_egr_ctl_psi_eop_info — AND-ed raw_status bits with the corresponding bit in the intr1_status register. Read only.
  [0] si_egr_ctl_psi_data_type_err — AND-ed raw_status bits with the corresponding bit in the intr1_status register. Read only.
0x32210 AIL_ee_sie_f_0_Raw_Interrupt_Status — (1 of 1, stride 0)
  [31:0] si_egr_iq_psi_sop_info — SI Ingress IQ per channel SOP received from PSI
0x32214 AIL_ee_sie_f_0_Raw_Set wo — (1 of 1, stride 0)
  [31:0] si_egr_iq_psi_sop_info — Sets the corresponding bit in the raw_status register when set. Write only, self-clears.
0x32218 AIL_ee_sie_f_0_Raw_Clear wo — (1 of 1, stride 0)
  [31:0] si_egr_iq_psi_sop_info — Clears the corresponding bit in the raw_status register when set. Write only, self-clears.
0x3221C AIL_ee_sie_f_0_EV0_Enable_Status — (1 of 1, stride 0)
  [31:0] si_egr_iq_psi_sop_info — When set allows the corresponding bit in the raw_status register to generate the intr_sts interrupt. Read only.
0x32220 AIL_ee_sie_f_0_EV0_Enable_Set wo — (1 of 1, stride 0)
  [31:0] si_egr_iq_psi_sop_info — Sets the corresponding bit in the enable register when set. Write only, self-clears.
0x32224 AIL_ee_sie_f_0_EV0_Enable_Clear wo — (1 of 1, stride 0)
  [31:0] si_egr_iq_psi_sop_info — Clears the corresponding bit in the enable register when set. Write only, self-clears.
0x32228 AIL_ee_sie_f_0_EV1_Enable_Status — (1 of 1, stride 0)
  [31:0] si_egr_iq_psi_sop_info — When set allows the corresponding bit in the raw_status register to generate the intr1_sts interrupt. Read only.
0x3222C AIL_ee_sie_f_0_EV1_Enable_Set wo — (1 of 1, stride 0)
  [31:0] si_egr_iq_psi_sop_info — Sets the corresponding bit in the intr1_status register when set. Write only, self-clears.
0x32230 AIL_ee_sie_f_0_EV1_Enable_Clear wo — (1 of 1, stride 0)
  [31:0] si_egr_iq_psi_sop_info — Clears the corresponding bit in the intr1_status register when set. Write only, self-clears.
0x32234 AIL_ee_sie_f_0_EV0_Enabled_Status — (1 of 1, stride 0)
  [31:0] si_egr_iq_psi_sop_info — AND-ed raw_status bits with the corresponding bit in the enable_status register. Read only.
0x32238 AIL_ee_sie_f_0_EV1_Enabled_Status — (1 of 1, stride 0)
  [31:0] si_egr_iq_psi_sop_info — AND-ed raw_status bits with the corresponding bit in the intr1_status register. Read only.
0x3223C AIL_ee_sie_f_1_Raw_Interrupt_Status — (1 of 1, stride 0)
  [31:0] si_egr_iq_psi_sop_info_64_32 — SI Ingress IQ per channel SOP received from PSI
0x32240 AIL_ee_sie_f_1_Raw_Set wo — (1 of 1, stride 0)
  [31:0] si_egr_iq_psi_sop_info_64_32 — Sets the corresponding bit in the raw_status register when set. Write only, self-clears.
0x32244 AIL_ee_sie_f_1_Raw_Clear wo — (1 of 1, stride 0)
  [31:0] si_egr_iq_psi_sop_info_64_32 — Clears the corresponding bit in the raw_status register when set. Write only, self-clears.
0x32248 AIL_ee_sie_f_1_EV0_Enable_Status — (1 of 1, stride 0)
  [31:0] si_egr_iq_psi_sop_info_64_32 — When set allows the corresponding bit in the raw_status register to generate the intr_sts interrupt. Read only.
0x3224C AIL_ee_sie_f_1_EV0_Enable_Set wo — (1 of 1, stride 0)
  [31:0] si_egr_iq_psi_sop_info_64_32 — Sets the corresponding bit in the enable register when set. Write only, self-clears.
0x32250 AIL_ee_sie_f_1_EV0_Enable_Clear wo — (1 of 1, stride 0)
  [31:0] si_egr_iq_psi_sop_info_64_32 — Clears the corresponding bit in the enable register when set. Write only, self-clears.
0x32254 AIL_ee_sie_f_1_EV1_Enable_Status — (1 of 1, stride 0)
  [31:0] si_egr_iq_psi_sop_info_64_32 — When set allows the corresponding bit in the raw_status register to generate the intr1_sts interrupt. Read only.
0x32258 AIL_ee_sie_f_1_EV1_Enable_Set wo — (1 of 1, stride 0)
  [31:0] si_egr_iq_psi_sop_info_64_32 — Sets the corresponding bit in the intr1_status register when set. Write only, self-clears.
0x3225C AIL_ee_sie_f_1_EV1_Enable_Clear wo — (1 of 1, stride 0)
  [31:0] si_egr_iq_psi_sop_info_64_32 — Clears the corresponding bit in the intr1_status register when set. Write only, self-clears.
0x32260 AIL_ee_sie_f_1_EV0_Enabled_Status — (1 of 1, stride 0)
  [31:0] si_egr_iq_psi_sop_info_64_32 — AND-ed raw_status bits with the corresponding bit in the enable_status register. Read only.
0x32264 AIL_ee_sie_f_1_EV1_Enabled_Status — (1 of 1, stride 0)
  [31:0] si_egr_iq_psi_sop_info_64_32 — AND-ed raw_status bits with the corresponding bit in the intr1_status register. Read only.
0x322C0 AIL_ee_sie_g_Raw_Interrupt_Status — (1 of 1, stride 0)
  [3:0] si_egr_ctl_psi_sop_info — SI Egress CTL per channel SOP received from PSI
0x322C4 AIL_ee_sie_g_Raw_Set wo — (1 of 1, stride 0)
  [3:0] si_egr_ctl_psi_sop_info — Sets the corresponding bit in the raw_status register when set. Write only, self-clears.
0x322C8 AIL_ee_sie_g_Raw_Clear wo — (1 of 1, stride 0)
  [3:0] si_egr_ctl_psi_sop_info — Clears the corresponding bit in the raw_status register when set. Write only, self-clears.
0x322CC AIL_ee_sie_g_EV0_Enable_Status — (1 of 1, stride 0)
  [3:0] si_egr_ctl_psi_sop_info — When set allows the corresponding bit in the raw_status register to generate the intr_sts interrupt. Read only.
0x322D0 AIL_ee_sie_g_EV0_Enable_Set wo — (1 of 1, stride 0)
  [3:0] si_egr_ctl_psi_sop_info — Sets the corresponding bit in the enable register when set. Write only, self-clears.
0x322D4 AIL_ee_sie_g_EV0_Enable_Clear wo — (1 of 1, stride 0)
  [3:0] si_egr_ctl_psi_sop_info — Clears the corresponding bit in the enable register when set. Write only, self-clears.
0x322D8 AIL_ee_sie_g_EV1_Enable_Status — (1 of 1, stride 0)
  [3:0] si_egr_ctl_psi_sop_info — When set allows the corresponding bit in the raw_status register to generate the intr1_sts interrupt. Read only.
0x322DC AIL_ee_sie_g_EV1_Enable_Set wo — (1 of 1, stride 0)
  [3:0] si_egr_ctl_psi_sop_info — Sets the corresponding bit in the intr1_status register when set. Write only, self-clears.
0x322E0 AIL_ee_sie_g_EV1_Enable_Clear wo — (1 of 1, stride 0)
  [3:0] si_egr_ctl_psi_sop_info — Clears the corresponding bit in the intr1_status register when set. Write only, self-clears.
0x322E4 AIL_ee_sie_g_EV0_Enabled_Status — (1 of 1, stride 0)
  [3:0] si_egr_ctl_psi_sop_info — AND-ed raw_status bits with the corresponding bit in the enable_status register. Read only.
0x322E8 AIL_ee_sie_g_EV1_Enabled_Status — (1 of 1, stride 0)
  [3:0] si_egr_ctl_psi_sop_info — AND-ed raw_status bits with the corresponding bit in the intr1_status register. Read only.
0x32370 AIL_vbusclk_orig_reg — (1 of 1, stride 0)
  [19] orig_ee_19 — Reserved.
  [18] orig_ee_18 — Reserved.
  [17] orig_ee_17 — Reserved.
  [16] orig_ee_16 — If set a bit is set in the ee_sie_g register.
  [15] orig_ee_15 — Reserved.
  [14] orig_ee_14 — Reserved.
  [13] orig_ee_13 — If set a bit is set in the ee_sie_f_1 register.
  [12] orig_ee_12 — If set a bit is set in the ee_sie_f_0 register.
  [11] orig_ee_11 — If set a bit is set in the ee_sie_e register.
  [10] orig_ee_10 — If set a bit is set in the ee_sie_d register.
  [9] orig_ee_9 — Reserved.
  [8] orig_ee_8 — Reserved.
  [7] orig_ee_7 — Reserved.
  [6] orig_ee_6 — If set a bit is set in the ee_sii_h_d register.
  [5] orig_ee_5 — Reserved.
  [4] orig_ee_4 — Reserved.
  [3] orig_ee_3 — If set a bit is set in the ee_sii_g_1 register.
  [2] orig_ee_2 — If set a bit is set in the ee_sii_g_0 register.
  [1] orig_ee_1 — If set a bit is set in the ee_sii_f register.
  [0] orig_ee_0 — If set a bit is set in the ee_sii_e register.
0x34000 AIL_rm_0_Raw_Interrupt_Status — (1 of 1, stride 0)
  [25] rm_rst — RM reset is an SOC reset generated when the L1inband rst signal is valid high for 5 consecutive frames.
  [24] lof_state — lof state indicates the Rx state machine lost frame.
  [23] hfnsync_state — hfnsync state indicates that the Rx state has recognized the hfn value in CPRI mode.
  [22] lof_err — An lof error has occurred in the Rx state machine, indicating that a valid frame format is no longer received from the ser-des interface.
  [21] los_err — An los error has occurred in the Rx state machine, indicating that a valid signal is no longer received from the ser-des interface.
  [20] rcvd_rst — Recevied a rst set high in the CPRI L1inband signal while in CPRI mode.
  [19] rcvd_sdi — Recevied an sdi (Signal Defect Indicator) in the CPRI L1inband signal while in CPRI mode.
  [18] rcvd_rai — Recieved an rai (Remote Alarm Indicator) in the CPRI L1inband signal while in CPRI mode.
  [17] rcvd_lof — Recieved an lof in the CPRI L1inband signal while in CPRI mode.
  [16] rcvd_los — Recieved an los in the CPRI L1inband signal while in CPRI mode.
  [15] rx_fifo_ovf — RX Fifo has overflowed, indicating the rx clock is faster than the system clock.
  [14] loc_det — Loc was detected in the RM block as determined by the clock monitor circuit.
  [13] k30p7_det — A k30p7 was detected in the RM received byte data.
  [12] missing_k28p7 — An expected k28p7 was missed by the Rx state machine.
  [11] missing_k28p5 — An expected k28p5 was missed by the Rx state machine.
  [10] block_bndry_det — The RM has detected a valid block boundary.
  [9] frame_bndry_det — The RM has detected Frame boundary.
  [8] lcv_det — lcv error detected.
  [7] num_los_det — Number of los detected over los_thold number.
  [6] rm_status_state5 — The Rx state machine of the RM is in state5, indicating the link is in OBSAI scramberl received state.
  [5] rm_status_state4 — The Rx state machine of the RM is in state4, indicating the link is in OBSAI scrambler detect state.
  [4] rm_status_state3 — The Rx state machine of the RM is in state3, indicating the link is in sync state.
  [3] rm_status_state2 — The Rx state machine of the RM is in state2, indicating the link is in pre-sync state.
  [2] rm_status_state1 — The Rx state machine of the RM is in state1, indicating the link is in K character recieved state.
  [1] rm_status_state0 — The Rx state machine of the RM is in state0, indicating the link is idle.
  [0] sync_status_change — Sync status has changed in the Rx state machine.
0x34004 AIL_rm_0_Raw_Set wo — (1 of 1, stride 0)
  [25] rm_rst — Sets the corresponding bit in the raw_status register when set. Write only, self-clears.
  [24] lof_state — Sets the corresponding bit in the raw_status register when set. Write only, self-clears.
  [23] hfnsync_state — Sets the corresponding bit in the raw_status register when set. Write only, self-clears.
  [22] lof_err — Sets the corresponding bit in the raw_status register when set. Write only, self-clears.
  [21] los_err — Sets the corresponding bit in the raw_status register when set. Write only, self-clears.
  [20] rcvd_rst — Sets the corresponding bit in the raw_status register when set. Write only, self-clears.
  [19] rcvd_sdi — Sets the corresponding bit in the raw_status register when set. Write only, self-clears.
  [18] rcvd_rai — Sets the corresponding bit in the raw_status register when set. Write only, self-clears.
  [17] rcvd_lof — Sets the corresponding bit in the raw_status register when set. Write only, self-clears.
  [16] rcvd_los — Sets the corresponding bit in the raw_status register when set. Write only, self-clears.
  [15] rx_fifo_ovf — Sets the corresponding bit in the raw_status register when set. Write only, self-clears.
  [14] loc_det — Sets the corresponding bit in the raw_status register when set. Write only, self-clears.
  [13] k30p7_det — Sets the corresponding bit in the raw_status register when set. Write only, self-clears.
  [12] missing_k28p7 — Sets the corresponding bit in the raw_status register when set. Write only, self-clears.
  [11] missing_k28p5 — Sets the corresponding bit in the raw_status register when set. Write only, self-clears.
  [10] block_bndry_det — Sets the corresponding bit in the raw_status register when set. Write only, self-clears.
  [9] frame_bndry_det — Sets the corresponding bit in the raw_status register when set. Write only, self-clears.
  [8] lcv_det — Sets the corresponding bit in the raw_status register when set. Write only, self-clears.
  [7] num_los_det — Sets the corresponding bit in the raw_status register when set. Write only, self-clears.
  [n+1] rm_status_state{n} (n=0..5) — Sets the corresponding bit in the raw_status register when set. Write only, self-clears.
  [0] sync_status_change — Sets the corresponding bit in the raw_status register when set. Write only, self-clears.
